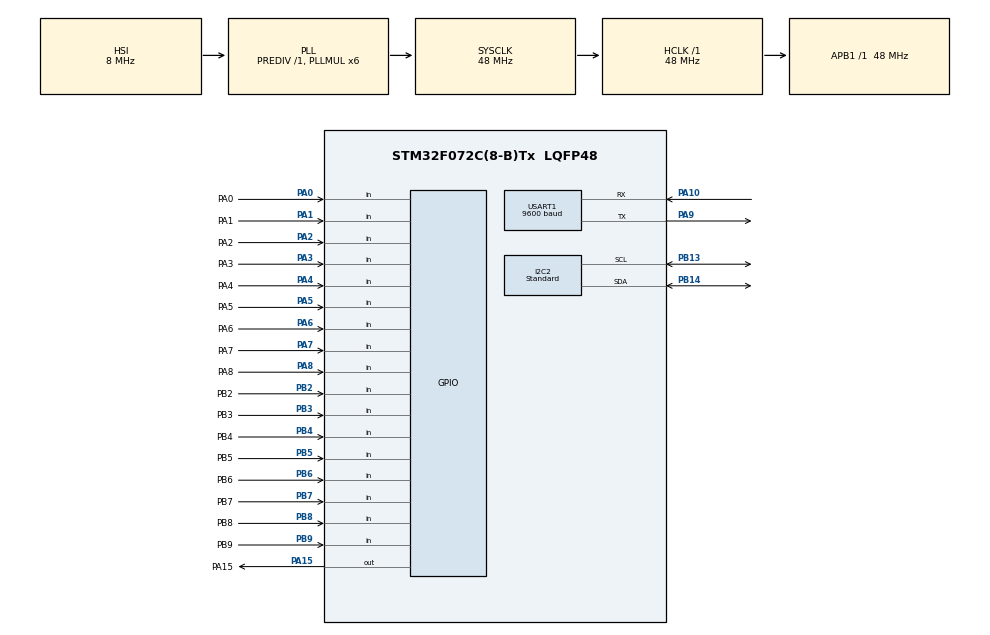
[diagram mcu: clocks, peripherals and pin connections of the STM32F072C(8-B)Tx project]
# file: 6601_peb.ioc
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I2C2.I2C_Fall_Time=100
I2C2.I2C_Rise_Time=100
I2C2.I2C_Speed_Mode=I2C_Standard
I2C2.OwnAddress=0x0A
I2C2.Speed=100
I2C2.Timing=0x10805D88
Mcu.Family=STM32F0
Mcu.Name=STM32F072C(8-B)Tx
Mcu.Package=LQFP48
NVIC.I2C2_IRQn=true\:0\:0\:false\:false\:true\:true
PA0.GPIO_Label=PA0
PA0.Signal=GPIO_Input
PA1.GPIO_Label=PA1
PA1.Signal=GPIO_Input
PA10.Mode=Asynchronous
PA10.Signal=USART1_RX
PA13.Mode=Serial_Wire
PA13.Signal=SYS_SWDIO
PA14.Mode=Serial_Wire
PA14.Signal=SYS_SWCLK
PA15.GPIO_Label=PA15
PA15.GPIO_ModeDefaultOutputPP=GPIO_MODE_OUTPUT_OD
PA15.GPIO_Speed=GPIO_SPEED_FREQ_MEDIUM
PA15.PinState=GPIO_PIN_SET
PA15.Signal=GPIO_Output
PA2.GPIO_Label=PA2
PA2.Signal=GPIO_Input
PA3.GPIO_Label=PA3
PA3.Signal=GPIO_Input
PA4.GPIO_Label=PA4
PA4.Signal=GPIO_Input
PA5.GPIO_Label=PA5
PA5.Signal=GPIO_Input
PA6.GPIO_Label=PA6
PA6.Signal=GPIO_Input
PA7.GPIO_Label=PA7
PA7.Signal=GPIO_Input
PA8.GPIO_Label=PA8
PA8.Signal=GPIO_Input
PA9.Mode=Asynchronous
PA9.Signal=USART1_TX
PB13.GPIO_Mode=GPIO_MODE_AF_OD
PB13.GPIO_PuPdOD=GPIO_NOPULL
PB13.GPIO_Speed=GPIO_SPEED_FREQ_HIGH
PB13.Mode=I2C
PB13.Signal=I2C2_SCL
PB14.GPIO_Mode=GPIO_MODE_AF_OD
PB14.GPIO_PuPdOD=GPIO_NOPULL
PB14.GPIO_Speed=GPIO_SPEED_FREQ_HIGH
PB14.Mode=I2C
PB14.Signal=I2C2_SDA
PB2.GPIO_Label=PB2
PB2.Signal=GPIO_Input
PB3.GPIO_Label=PB3
PB3.Signal=GPIO_Input
PB4.GPIO_Label=PB4
PB4.Signal=GPIO_Input
PB5.GPIO_Label=PB5
PB5.Signal=GPIO_Input
PB6.GPIO_Label=PB6
PB6.Signal=GPIO_Input
PB7.GPIO_Label=PB7
PB7.Signal=GPIO_Input
PB8.GPIO_Label=PB8
PB8.Signal=GPIO_Input
PB9.GPIO_Label=PB9
PB9.Signal=GPIO_Input
ProjectManager.HeapSize=0x200
ProjectManager.StackSize=0x400
ProjectManager.TargetToolchain=MDK-ARM V5
RCC.AHBFreq_Value=48000000
RCC.APB1Freq_Value=48000000
RCC.APB1TimFreq_Value=48000000
RCC.HCLKFreq_Value=48000000
RCC.PLLMUL=RCC_PLL_MUL6
RCC.SYSCLKFreq_VALUE=48000000
RCC.SYSCLKSource=RCC_SYSCLKSOURCE_PLLCLK
USART1.BaudRate=9600
USART1.VirtualMode-Asynchronous=VM_ASYNC
board=custom

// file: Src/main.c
/**
  ******************************************************************************
  * @file           : main.c
  * @brief          : Main program body
  ******************************************************************************
  ** This notice applies to any and all portions of this file
  * that are not between comment pairs USER CODE BEGIN and
  * USER CODE END. Other portions of this file, whether
  * inserted by the user or by software development tools
  * are owned by their respective copyright owners.
  *
  * COPYRIGHT(c) 2019 STMicroelectronics
  *
  * Redistribution and use in source and binary forms, with or without modification,
  * are permitted provided that the following conditions are met:
  *   1. Redistributions of source code must retain the above copyright notice,
  *      this list of conditions and the following disclaimer.
  *   2. Redistributions in binary form must reproduce the above copyright notice,
  *      this list of conditions and the following disclaimer in the documentation
  *      and/or other materials provided with the distribution.
  *   3. Neither the name of STMicroelectronics nor the names of its contributors
  *      may be used to endorse or promote products derived from this software
  *      without specific prior written permission.
  *
  * THIS SOFTWARE IS PROVIDED BY THE COPYRIGHT HOLDERS AND CONTRIBUTORS "AS IS"
  * AND ANY EXPRESS OR IMPLIED WARRANTIES, INCLUDING, BUT NOT LIMITED TO, THE
  * IMPLIED WARRANTIES OF MERCHANTABILITY AND FITNESS FOR A PARTICULAR PURPOSE ARE
  * DISCLAIMED. IN NO EVENT SHALL THE COPYRIGHT HOLDER OR CONTRIBUTORS BE LIABLE
  * FOR ANY DIRECT, INDIRECT, INCIDENTAL, SPECIAL, EXEMPLARY, OR CONSEQUENTIAL
  * DAMAGES (INCLUDING, BUT NOT LIMITED TO, PROCUREMENT OF SUBSTITUTE GOODS OR
  * SERVICES; LOSS OF USE, DATA, OR PROFITS; OR BUSINESS INTERRUPTION) HOWEVER
  * CAUSED AND ON ANY THEORY OF LIABILITY, WHETHER IN CONTRACT, STRICT LIABILITY,
  * OR TORT (INCLUDING NEGLIGENCE OR OTHERWISE) ARISING IN ANY WAY OUT OF THE USE
  * OF THIS SOFTWARE, EVEN IF ADVISED OF THE POSSIBILITY OF SUCH DAMAGE.
  *
  ******************************************************************************
  */
#include "main.h"
#include "stm32f0xx_hal.h"

/* USER CODE BEGIN Includes */
#include "peb_6601.h"
/* USER CODE END Includes */

I2C_HandleTypeDef hi2c2;

UART_HandleTypeDef huart1;

/* USER CODE BEGIN PV */
/* Private variables ---------------------------------------------------------*/

/* USER CODE END PV */

void SystemClock_Config(void);
static void MX_GPIO_Init(void);
static void MX_I2C2_Init(void);
static void MX_USART1_UART_Init(void);

/* USER CODE BEGIN PFP */
/* Private function prototypes -----------------------------------------------*/

/* USER CODE END PFP */

int main(void)
{

  /* MCU Configuration----------------------------------------------------------*/

  /* Reset of all peripherals, Initializes the Flash interface and the Systick. */
  HAL_Init();

  /* Configure the system clock */
  SystemClock_Config();

  /* Initialize all configured peripherals */
  MX_GPIO_Init();
  MX_I2C2_Init();
  MX_USART1_UART_Init();
  /* USER CODE BEGIN 2 */
	//HAL_GPIO_WritePin(GPIOA,PA15_Pin,GPIO_PIN_SET);
	HAL_Delay(3000);
  /* USER CODE END 2 */

  /* Infinite loop */
  while (1)
  {

  /* USER CODE BEGIN 3 */
		PEB_6601();
  }
  /* USER CODE END 3 */

}

void SystemClock_Config(void)
{

  RCC_OscInitTypeDef RCC_OscInitStruct;
  RCC_ClkInitTypeDef RCC_ClkInitStruct;
  RCC_PeriphCLKInitTypeDef PeriphClkInit;

    /**Initializes the CPU, AHB and APB busses clocks
    */
  RCC_OscInitStruct.OscillatorType = RCC_OSCILLATORTYPE_HSI;
  RCC_OscInitStruct.HSIState = RCC_HSI_ON;
  RCC_OscInitStruct.HSICalibrationValue = 16;
  RCC_OscInitStruct.PLL.PLLState = RCC_PLL_ON;
  RCC_OscInitStruct.PLL.PLLSource = RCC_PLLSOURCE_HSI;
  RCC_OscInitStruct.PLL.PLLMUL = RCC_PLL_MUL6;
  RCC_OscInitStruct.PLL.PREDIV = RCC_PREDIV_DIV1;
  if (HAL_RCC_OscConfig(&RCC_OscInitStruct) != HAL_OK)
  {
    _Error_Handler(__FILE__, __LINE__);
  }

    /**Initializes the CPU, AHB and APB busses clocks
    */
  RCC_ClkInitStruct.ClockType = RCC_CLOCKTYPE_HCLK|RCC_CLOCKTYPE_SYSCLK
                              |RCC_CLOCKTYPE_PCLK1;
  RCC_ClkInitStruct.SYSCLKSource = RCC_SYSCLKSOURCE_PLLCLK;
  RCC_ClkInitStruct.AHBCLKDivider = RCC_SYSCLK_DIV1;
  RCC_ClkInitStruct.APB1CLKDivider = RCC_HCLK_DIV1;

  if (HAL_RCC_ClockConfig(&RCC_ClkInitStruct, FLASH_LATENCY_1) != HAL_OK)
  {
    _Error_Handler(__FILE__, __LINE__);
  }

  PeriphClkInit.PeriphClockSelection = RCC_PERIPHCLK_USART1;
  PeriphClkInit.Usart1ClockSelection = RCC_USART1CLKSOURCE_PCLK1;
  if (HAL_RCCEx_PeriphCLKConfig(&PeriphClkInit) != HAL_OK)
  {
    _Error_Handler(__FILE__, __LINE__);
  }

    /**Configure the Systick interrupt time
    */
  HAL_SYSTICK_Config(HAL_RCC_GetHCLKFreq()/1000);

    /**Configure the Systick
    */
  HAL_SYSTICK_CLKSourceConfig(SYSTICK_CLKSOURCE_HCLK);

  /* SysTick_IRQn interrupt configuration */
  HAL_NVIC_SetPriority(SysTick_IRQn, 0, 0);
}

/* I2C2 init function */
static void MX_I2C2_Init(void)
{

  hi2c2.Instance = I2C2;
  hi2c2.Init.Timing = 0x10805D88;
  hi2c2.Init.OwnAddress1 = 20;
  hi2c2.Init.AddressingMode = I2C_ADDRESSINGMODE_7BIT;
  hi2c2.Init.DualAddressMode = I2C_DUALADDRESS_DISABLE;
  hi2c2.Init.OwnAddress2 = 0;
  hi2c2.Init.OwnAddress2Masks = I2C_OA2_NOMASK;
  hi2c2.Init.GeneralCallMode = I2C_GENERALCALL_DISABLE;
  hi2c2.Init.NoStretchMode = I2C_NOSTRETCH_DISABLE;
  if (HAL_I2C_Init(&hi2c2) != HAL_OK)
  {
    _Error_Handler(__FILE__, __LINE__);
  }

    /**Configure Analogue filter
    */
  if (HAL_I2CEx_ConfigAnalogFilter(&hi2c2, I2C_ANALOGFILTER_ENABLE) != HAL_OK)
  {
    _Error_Handler(__FILE__, __LINE__);
  }

    /**Configure Digital filter
    */
  if (HAL_I2CEx_ConfigDigitalFilter(&hi2c2, 0) != HAL_OK)
  {
    _Error_Handler(__FILE__, __LINE__);
  }

}

/* USART1 init function */
static void MX_USART1_UART_Init(void)
{

  huart1.Instance = USART1;
  huart1.Init.BaudRate = 9600;
  huart1.Init.WordLength = UART_WORDLENGTH_8B;
  huart1.Init.StopBits = UART_STOPBITS_1;
  huart1.Init.Parity = UART_PARITY_NONE;
  huart1.Init.Mode = UART_MODE_TX_RX;
  huart1.Init.HwFlowCtl = UART_HWCONTROL_NONE;
  huart1.Init.OverSampling = UART_OVERSAMPLING_16;
  huart1.Init.OneBitSampling = UART_ONE_BIT_SAMPLE_DISABLE;
  huart1.AdvancedInit.AdvFeatureInit = UART_ADVFEATURE_NO_INIT;
  if (HAL_UART_Init(&huart1) != HAL_OK)
  {
    _Error_Handler(__FILE__, __LINE__);
  }

}

/** Configure pins as
        * Analog
        * Input
        * Output
        * EVENT_OUT
        * EXTI
*/
static void MX_GPIO_Init(void)
{

  GPIO_InitTypeDef GPIO_InitStruct;

  /* GPIO Ports Clock Enable */
  __HAL_RCC_GPIOA_CLK_ENABLE();
  __HAL_RCC_GPIOB_CLK_ENABLE();

  /*Configure GPIO pin Output Level */
  HAL_GPIO_WritePin(PA15_GPIO_Port, PA15_Pin, GPIO_PIN_SET);

  /*Configure GPIO pins : PA0_Pin PA1_Pin PA2_Pin PA3_Pin
                           PA4_Pin PA5_Pin PA6_Pin PA7_Pin
                           PA8_Pin */
  GPIO_InitStruct.Pin = PA0_Pin|PA1_Pin|PA2_Pin|PA3_Pin
                          |PA4_Pin|PA5_Pin|PA6_Pin|PA7_Pin
                          |PA8_Pin;
  GPIO_InitStruct.Mode = GPIO_MODE_INPUT;
  GPIO_InitStruct.Pull = GPIO_NOPULL;
  HAL_GPIO_Init(GPIOA, &GPIO_InitStruct);

  /*Configure GPIO pins : PB2_Pin PB3_Pin PB4_Pin PB5_Pin
                           PB6_Pin PB7_Pin PB8_Pin PB9_Pin */
  GPIO_InitStruct.Pin = PB2_Pin|PB3_Pin|PB4_Pin|PB5_Pin
                          |PB6_Pin|PB7_Pin|PB8_Pin|PB9_Pin;
  GPIO_InitStruct.Mode = GPIO_MODE_INPUT;
  GPIO_InitStruct.Pull = GPIO_NOPULL;
  HAL_GPIO_Init(GPIOB, &GPIO_InitStruct);

  /*Configure GPIO pin : PA15_Pin */
  GPIO_InitStruct.Pin = PA15_Pin;
  GPIO_InitStruct.Mode = GPIO_MODE_OUTPUT_OD;
  GPIO_InitStruct.Pull = GPIO_NOPULL;
  GPIO_InitStruct.Speed = GPIO_SPEED_FREQ_MEDIUM;
  HAL_GPIO_Init(PA15_GPIO_Port, &GPIO_InitStruct);

}

void _Error_Handler(char *file, int line)
{
  while(1)
  {
  }
}

/************************ (C) COPYRIGHT STMicroelectronics *****END OF FILE****/
